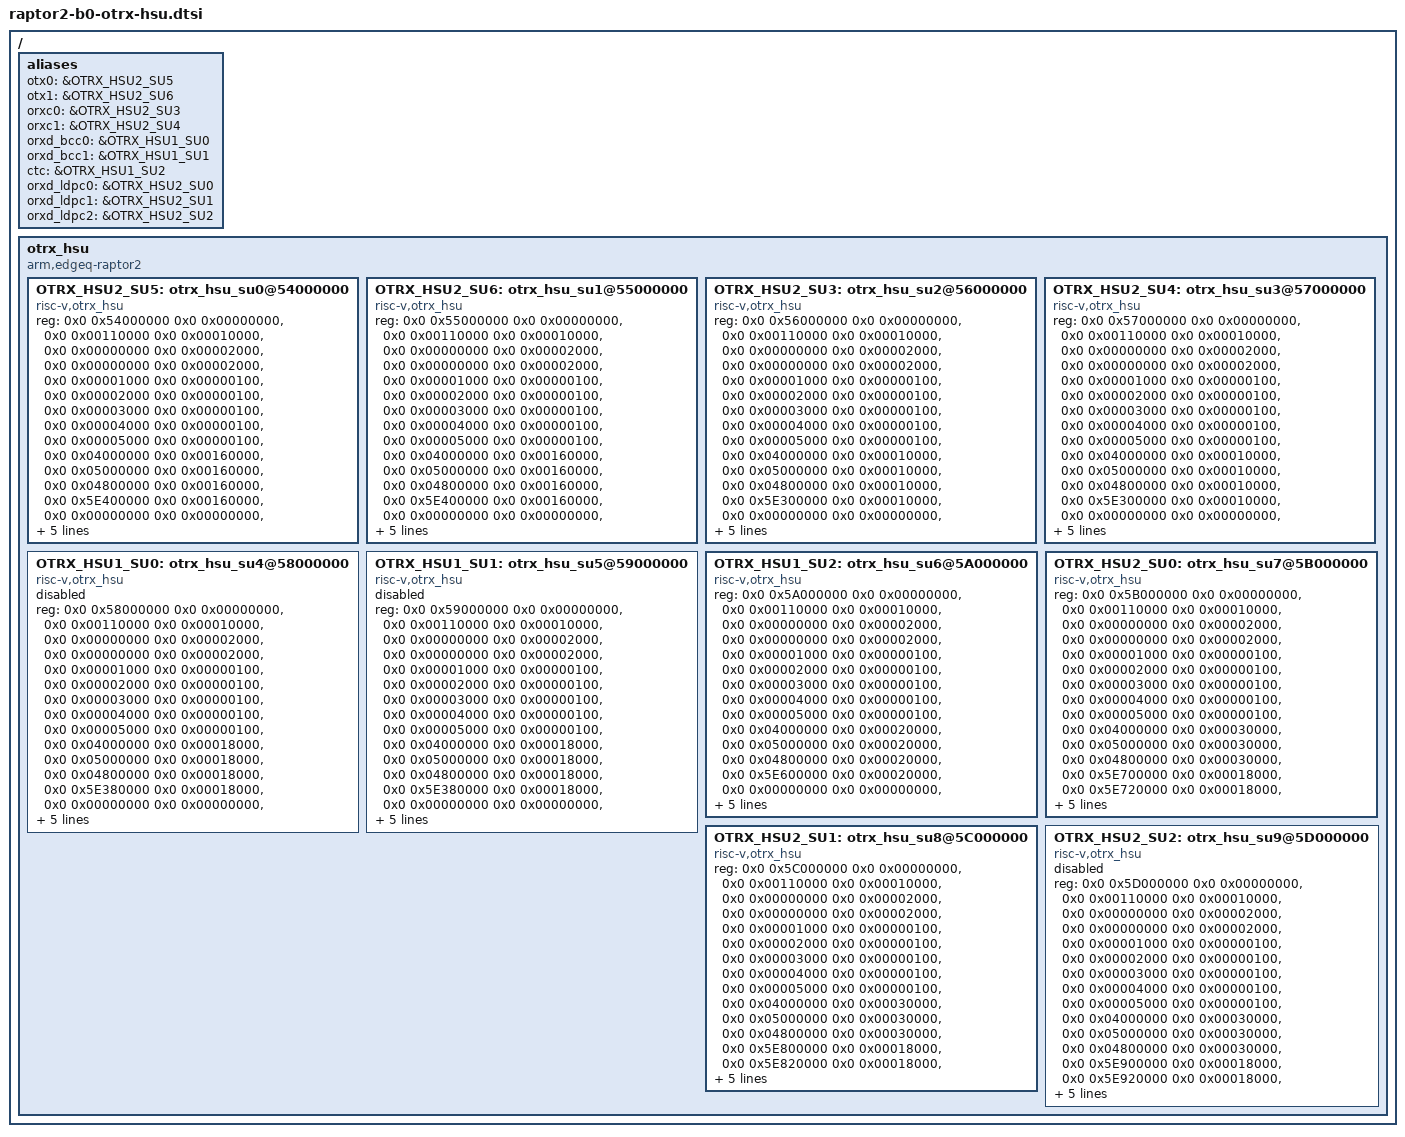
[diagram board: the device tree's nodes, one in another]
// SPDX-License-Identifier: GPL-2.0
/*
 * EdgeQ Inc.
 *
 * EdgeQ Raptor2 OTRX-HSU DTS
 */

/ {
	aliases {
		otx0 = &OTRX_HSU2_SU5;
		otx1 = &OTRX_HSU2_SU6;
		orxc0 = &OTRX_HSU2_SU3;
		orxc1 = &OTRX_HSU2_SU4;
		orxd_bcc0 = &OTRX_HSU1_SU0;
		orxd_bcc1 = &OTRX_HSU1_SU1;
		ctc = &OTRX_HSU1_SU2;
		orxd_ldpc0 = &OTRX_HSU2_SU0;
		orxd_ldpc1 = &OTRX_HSU2_SU1;
		orxd_ldpc2 = &OTRX_HSU2_SU2;
	};

	otrx_hsu {
		compatible = "arm,edgeq-raptor2";
		#address-cells = <2>;
		#size-cells = <2>;

		OTRX_HSU2_SU5: otrx_hsu_su0@54000000 {
			compatible = "risc-v,otrx_hsu";
			device_type = "su";
			#address-cells = <2>;
			#size-cells = <2>;
			ranges;
			reg =	<0x0 0x54000000 0x0 0x00000000>,
				<0x0 0x00110000 0x0 0x00010000>,
				<0x0 0x00000000 0x0 0x00002000>,
				<0x0 0x00000000 0x0 0x00002000>,
				<0x0 0x00001000 0x0 0x00000100>,
				<0x0 0x00002000 0x0 0x00000100>,
				<0x0 0x00003000 0x0 0x00000100>,
				<0x0 0x00004000 0x0 0x00000100>,
				<0x0 0x00005000 0x0 0x00000100>,
				<0x0 0x04000000 0x0 0x00160000>,
				<0x0 0x05000000 0x0 0x00160000>,
				<0x0 0x04800000 0x0 0x00160000>,
				<0x0 0x5E400000 0x0 0x00160000>,
				<0x0 0x00000000 0x0 0x00000000>,
				<0x0 0x00000000 0x0 0x00004000>,
				<0x0 0x00080000 0x0 0x00010000>;
			reg-names = "sudev_base", "cpu", "d-cache", "i-cache", "suinfo_offset",
				"suconf_offset", "suau_offset", "sustats_offset", "sudbg_offset",
				"lmem_addr_local_wb", "lmem_addr_local_unc", "lmem_addr_local_wt",
				"lmem_e1", "lmem_e1_b2", "ilmoffs", "dlmoffs";
			enable-method = "reset-vector";
			sudev = <&SUDEV>;
			sumem = <&SUMEM>;
			status = "okay";
		};

		OTRX_HSU2_SU6: otrx_hsu_su1@55000000 {
			compatible = "risc-v,otrx_hsu";
			device_type = "su";
			#address-cells = <2>;
			#size-cells = <2>;
			ranges;
			reg =	<0x0 0x55000000 0x0 0x00000000>,
				<0x0 0x00110000 0x0 0x00010000>,
				<0x0 0x00000000 0x0 0x00002000>,
				<0x0 0x00000000 0x0 0x00002000>,
				<0x0 0x00001000 0x0 0x00000100>,
				<0x0 0x00002000 0x0 0x00000100>,
				<0x0 0x00003000 0x0 0x00000100>,
				<0x0 0x00004000 0x0 0x00000100>,
				<0x0 0x00005000 0x0 0x00000100>,
				<0x0 0x04000000 0x0 0x00160000>,
				<0x0 0x05000000 0x0 0x00160000>,
				<0x0 0x04800000 0x0 0x00160000>,
				<0x0 0x5E400000 0x0 0x00160000>,
				<0x0 0x00000000 0x0 0x00000000>,
				<0x0 0x00000000 0x0 0x00004000>,
				<0x0 0x00080000 0x0 0x00010000>;
			reg-names = "sudev_base", "cpu", "d-cache", "i-cache", "suinfo_offset",
				"suconf_offset", "suau_offset", "sustats_offset", "sudbg_offset",
				"lmem_addr_local_wb", "lmem_addr_local_unc", "lmem_addr_local_wt",
				"lmem_e1", "lmem_e1_b2", "ilmoffs", "dlmoffs";
			enable-method = "reset-vector";
			sudev = <&SUDEV>;
			sumem = <&SUMEM>;
			status = "okay";
		};

		OTRX_HSU2_SU3: otrx_hsu_su2@56000000 {
			compatible = "risc-v,otrx_hsu";
			device_type = "su";
			#address-cells = <2>;
			#size-cells = <2>;
			ranges;
			reg =	<0x0 0x56000000 0x0 0x00000000>,
				<0x0 0x00110000 0x0 0x00010000>,
				<0x0 0x00000000 0x0 0x00002000>,
				<0x0 0x00000000 0x0 0x00002000>,
				<0x0 0x00001000 0x0 0x00000100>,
				<0x0 0x00002000 0x0 0x00000100>,
				<0x0 0x00003000 0x0 0x00000100>,
				<0x0 0x00004000 0x0 0x00000100>,
				<0x0 0x00005000 0x0 0x00000100>,
				<0x0 0x04000000 0x0 0x00010000>,
				<0x0 0x05000000 0x0 0x00010000>,
				<0x0 0x04800000 0x0 0x00010000>,
				<0x0 0x5E300000 0x0 0x00010000>,
				<0x0 0x00000000 0x0 0x00000000>,
				<0x0 0x00000000 0x0 0x00004000>,
				<0x0 0x00080000 0x0 0x00010000>;
			reg-names = "sudev_base", "cpu", "d-cache", "i-cache", "suinfo_offset",
				"suconf_offset", "suau_offset", "sustats_offset", "sudbg_offset",
				"lmem_addr_local_wb", "lmem_addr_local_unc", "lmem_addr_local_wt",
				"lmem_e1", "lmem_e1_b2", "ilmoffs", "dlmoffs";
			enable-method = "reset-vector";
			sudev = <&SUDEV>;
			sumem = <&SUMEM>;
			status = "okay";
		};

		OTRX_HSU2_SU4: otrx_hsu_su3@57000000 {
			compatible = "risc-v,otrx_hsu";
			device_type = "su";
			#address-cells = <2>;
			#size-cells = <2>;
			ranges;
			reg =	<0x0 0x57000000 0x0 0x00000000>,
				<0x0 0x00110000 0x0 0x00010000>,
				<0x0 0x00000000 0x0 0x00002000>,
				<0x0 0x00000000 0x0 0x00002000>,
				<0x0 0x00001000 0x0 0x00000100>,
				<0x0 0x00002000 0x0 0x00000100>,
				<0x0 0x00003000 0x0 0x00000100>,
				<0x0 0x00004000 0x0 0x00000100>,
				<0x0 0x00005000 0x0 0x00000100>,
				<0x0 0x04000000 0x0 0x00010000>,
				<0x0 0x05000000 0x0 0x00010000>,
				<0x0 0x04800000 0x0 0x00010000>,
				<0x0 0x5E300000 0x0 0x00010000>,
				<0x0 0x00000000 0x0 0x00000000>,
				<0x0 0x00000000 0x0 0x00004000>,
				<0x0 0x00080000 0x0 0x00010000>;
			reg-names = "sudev_base", "cpu", "d-cache", "i-cache", "suinfo_offset",
				"suconf_offset", "suau_offset", "sustats_offset", "sudbg_offset",
				"lmem_addr_local_wb", "lmem_addr_local_unc", "lmem_addr_local_wt",
				"lmem_e1", "lmem_e1_b2", "ilmoffs", "dlmoffs";
			enable-method = "reset-vector";
			sudev = <&SUDEV>;
			sumem = <&SUMEM>;
			status = "okay";
		};

		OTRX_HSU1_SU0: otrx_hsu_su4@58000000 {
			compatible = "risc-v,otrx_hsu";
			device_type = "su";
			#address-cells = <2>;
			#size-cells = <2>;
			ranges;
			reg =	<0x0 0x58000000 0x0 0x00000000>,
				<0x0 0x00110000 0x0 0x00010000>,
				<0x0 0x00000000 0x0 0x00002000>,
				<0x0 0x00000000 0x0 0x00002000>,
				<0x0 0x00001000 0x0 0x00000100>,
				<0x0 0x00002000 0x0 0x00000100>,
				<0x0 0x00003000 0x0 0x00000100>,
				<0x0 0x00004000 0x0 0x00000100>,
				<0x0 0x00005000 0x0 0x00000100>,
				<0x0 0x04000000 0x0 0x00018000>,
				<0x0 0x05000000 0x0 0x00018000>,
				<0x0 0x04800000 0x0 0x00018000>,
				<0x0 0x5E380000 0x0 0x00018000>,
				<0x0 0x00000000 0x0 0x00000000>,
				<0x0 0x00000000 0x0 0x00004000>,
				<0x0 0x00080000 0x0 0x00008000>;
			reg-names = "sudev_base", "cpu", "d-cache", "i-cache", "suinfo_offset",
				"suconf_offset", "suau_offset", "sustats_offset", "sudbg_offset",
				"lmem_addr_local_wb", "lmem_addr_local_unc", "lmem_addr_local_wt",
				"lmem_e1", "lmem_e1_b2", "ilmoffs", "dlmoffs";
			enable-method = "reset-vector";
			sudev = <&SUDEV>;
			sumem = <&SUMEM>;
			status = "disabled";
		};

		OTRX_HSU1_SU1: otrx_hsu_su5@59000000 {
			compatible = "risc-v,otrx_hsu";
			device_type = "su";
			#address-cells = <2>;
			#size-cells = <2>;
			ranges;
			reg =	<0x0 0x59000000 0x0 0x00000000>,
				<0x0 0x00110000 0x0 0x00010000>,
				<0x0 0x00000000 0x0 0x00002000>,
				<0x0 0x00000000 0x0 0x00002000>,
				<0x0 0x00001000 0x0 0x00000100>,
				<0x0 0x00002000 0x0 0x00000100>,
				<0x0 0x00003000 0x0 0x00000100>,
				<0x0 0x00004000 0x0 0x00000100>,
				<0x0 0x00005000 0x0 0x00000100>,
				<0x0 0x04000000 0x0 0x00018000>,
				<0x0 0x05000000 0x0 0x00018000>,
				<0x0 0x04800000 0x0 0x00018000>,
				<0x0 0x5E380000 0x0 0x00018000>,
				<0x0 0x00000000 0x0 0x00000000>,
				<0x0 0x00000000 0x0 0x00004000>,
				<0x0 0x00080000 0x0 0x00008000>;
			reg-names = "sudev_base", "cpu", "d-cache", "i-cache", "suinfo_offset",
				"suconf_offset", "suau_offset", "sustats_offset", "sudbg_offset",
				"lmem_addr_local_wb", "lmem_addr_local_unc", "lmem_addr_local_wt",
				"lmem_e1", "lmem_e1_b2", "ilmoffs", "dlmoffs";
			enable-method = "reset-vector";
			sudev = <&SUDEV>;
			sumem = <&SUMEM>;
			status = "disabled";
		};

		OTRX_HSU1_SU2: otrx_hsu_su6@5A000000 {
			compatible = "risc-v,otrx_hsu";
			device_type = "su";
			#address-cells = <2>;
			#size-cells = <2>;
			ranges;
			reg =	<0x0 0x5A000000 0x0 0x00000000>,
				<0x0 0x00110000 0x0 0x00010000>,
				<0x0 0x00000000 0x0 0x00002000>,
				<0x0 0x00000000 0x0 0x00002000>,
				<0x0 0x00001000 0x0 0x00000100>,
				<0x0 0x00002000 0x0 0x00000100>,
				<0x0 0x00003000 0x0 0x00000100>,
				<0x0 0x00004000 0x0 0x00000100>,
				<0x0 0x00005000 0x0 0x00000100>,
				<0x0 0x04000000 0x0 0x00020000>,
				<0x0 0x05000000 0x0 0x00020000>,
				<0x0 0x04800000 0x0 0x00020000>,
				<0x0 0x5E600000 0x0 0x00020000>,
				<0x0 0x00000000 0x0 0x00000000>,
				<0x0 0x00000000 0x0 0x00004000>,
				<0x0 0x00080000 0x0 0x00008000>;
			reg-names = "sudev_base", "cpu", "d-cache", "i-cache", "suinfo_offset",
				"suconf_offset", "suau_offset", "sustats_offset", "sudbg_offset",
				"lmem_addr_local_wb", "lmem_addr_local_unc", "lmem_addr_local_wt",
				"lmem_e1", "lmem_e1_b2", "ilmoffs", "dlmoffs";
			enable-method = "reset-vector";
			sudev = <&SUDEV>;
			sumem = <&SUMEM>;
			status = "okay";
		};

		OTRX_HSU2_SU0: otrx_hsu_su7@5B000000 {
			compatible = "risc-v,otrx_hsu";
			device_type = "su";
			#address-cells = <2>;
			#size-cells = <2>;
			ranges;
			reg =	<0x0 0x5B000000 0x0 0x00000000>,
				<0x0 0x00110000 0x0 0x00010000>,
				<0x0 0x00000000 0x0 0x00002000>,
				<0x0 0x00000000 0x0 0x00002000>,
				<0x0 0x00001000 0x0 0x00000100>,
				<0x0 0x00002000 0x0 0x00000100>,
				<0x0 0x00003000 0x0 0x00000100>,
				<0x0 0x00004000 0x0 0x00000100>,
				<0x0 0x00005000 0x0 0x00000100>,
				<0x0 0x04000000 0x0 0x00030000>,
				<0x0 0x05000000 0x0 0x00030000>,
				<0x0 0x04800000 0x0 0x00030000>,
				<0x0 0x5E700000 0x0 0x00018000>,
				<0x0 0x5E720000 0x0 0x00018000>,
				<0x0 0x00000000 0x0 0x00004000>,
				<0x0 0x00080000 0x0 0x00010000>;
			reg-names = "sudev_base", "cpu", "d-cache", "i-cache", "suinfo_offset",
				"suconf_offset", "suau_offset", "sustats_offset", "sudbg_offset",
				"lmem_addr_local_wb", "lmem_addr_local_unc", "lmem_addr_local_wt",
				"lmem_e1", "lmem_e1_b2", "ilmoffs", "dlmoffs";
			enable-method = "reset-vector";
			sudev = <&SUDEV>;
			sumem = <&SUMEM>;
			status = "okay";
		};

		OTRX_HSU2_SU1: otrx_hsu_su8@5C000000 {
			compatible = "risc-v,otrx_hsu";
			device_type = "su";
			#address-cells = <2>;
			#size-cells = <2>;
			ranges;
			reg =	<0x0 0x5C000000 0x0 0x00000000>,
				<0x0 0x00110000 0x0 0x00010000>,
				<0x0 0x00000000 0x0 0x00002000>,
				<0x0 0x00000000 0x0 0x00002000>,
				<0x0 0x00001000 0x0 0x00000100>,
				<0x0 0x00002000 0x0 0x00000100>,
				<0x0 0x00003000 0x0 0x00000100>,
				<0x0 0x00004000 0x0 0x00000100>,
				<0x0 0x00005000 0x0 0x00000100>,
				<0x0 0x04000000 0x0 0x00030000>,
				<0x0 0x05000000 0x0 0x00030000>,
				<0x0 0x04800000 0x0 0x00030000>,
				<0x0 0x5E800000 0x0 0x00018000>,
				<0x0 0x5E820000 0x0 0x00018000>,
				<0x0 0x00000000 0x0 0x00004000>,
				<0x0 0x00080000 0x0 0x00010000>;
			reg-names = "sudev_base", "cpu", "d-cache", "i-cache", "suinfo_offset",
				"suconf_offset", "suau_offset", "sustats_offset", "sudbg_offset",
				"lmem_addr_local_wb", "lmem_addr_local_unc", "lmem_addr_local_wt",
				"lmem_e1", "lmem_e1_b2", "ilmoffs", "dlmoffs";
			enable-method = "reset-vector";
			sudev = <&SUDEV>;
			sumem = <&SUMEM>;
			status = "okay";
		};

		OTRX_HSU2_SU2: otrx_hsu_su9@5D000000 {
			compatible = "risc-v,otrx_hsu";
			device_type = "su";
			#address-cells = <2>;
			#size-cells = <2>;
			ranges;
			reg =	<0x0 0x5D000000 0x0 0x00000000>,
				<0x0 0x00110000 0x0 0x00010000>,
				<0x0 0x00000000 0x0 0x00002000>,
				<0x0 0x00000000 0x0 0x00002000>,
				<0x0 0x00001000 0x0 0x00000100>,
				<0x0 0x00002000 0x0 0x00000100>,
				<0x0 0x00003000 0x0 0x00000100>,
				<0x0 0x00004000 0x0 0x00000100>,
				<0x0 0x00005000 0x0 0x00000100>,
				<0x0 0x04000000 0x0 0x00030000>,
				<0x0 0x05000000 0x0 0x00030000>,
				<0x0 0x04800000 0x0 0x00030000>,
				<0x0 0x5E900000 0x0 0x00018000>,
				<0x0 0x5E920000 0x0 0x00018000>,
				<0x0 0x00000000 0x0 0x00004000>,
				<0x0 0x00080000 0x0 0x00010000>;
			reg-names = "sudev_base", "cpu", "d-cache", "i-cache", "suinfo_offset",
				"suconf_offset", "suau_offset", "sustats_offset", "sudbg_offset",
				"lmem_addr_local_wb", "lmem_addr_local_unc", "lmem_addr_local_wt",
				"lmem_e1", "lmem_e1_b2", "ilmoffs", "dlmoffs";
			enable-method = "reset-vector";
			sudev = <&SUDEV>;
			sumem = <&SUMEM>;
			status = "disabled";
		};
	};
};
